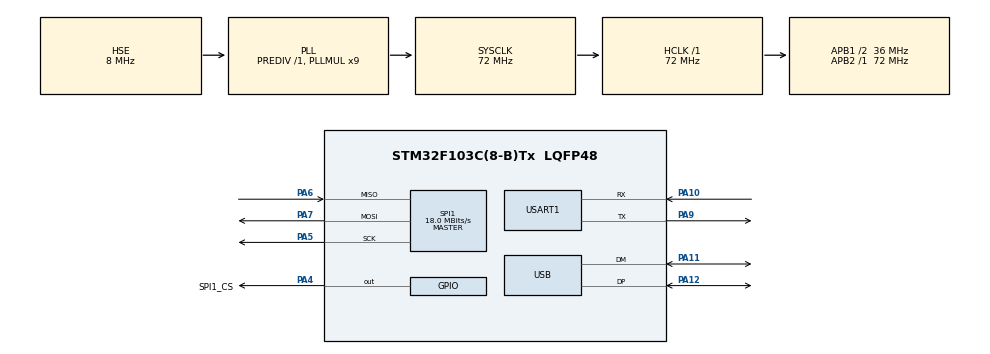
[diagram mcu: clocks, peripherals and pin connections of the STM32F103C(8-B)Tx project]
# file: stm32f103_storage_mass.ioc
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FATFS._CODE_PAGE=1
FATFS._FS_MINIMIZE=0
FATFS._FS_NORTC=0
FATFS._MAX_SS=4096
FATFS._MIN_SS=4096
FATFS._STRF_ENCODE=0
FATFS._USE_FASTSEEK=1
FATFS._USE_FIND=1
FATFS._USE_FORWARD=0
Mcu.Family=STM32F1
Mcu.Name=STM32F103C(8-B)Tx
Mcu.Package=LQFP48
NVIC.PriorityGroup=NVIC_PRIORITYGROUP_2
NVIC.USART1_IRQn=true\:3\:3\:true\:false\:true\:true\:true
NVIC.USB_LP_CAN1_RX0_IRQn=true\:0\:0\:false\:false\:true\:false\:true
PA10.Mode=Asynchronous
PA10.Signal=USART1_RX
PA11.Mode=Device
PA11.Signal=USB_DM
PA12.Mode=Device
PA12.Signal=USB_DP
PA13.Mode=Serial_Wire
PA13.Signal=SYS_JTMS-SWDIO
PA14.Mode=Serial_Wire
PA14.Signal=SYS_JTCK-SWCLK
PA4.GPIO_Label=SPI1_CS
PA4.GPIO_PuPd=GPIO_NOPULL
PA4.GPIO_Speed=GPIO_SPEED_FREQ_HIGH
PA4.PinState=GPIO_PIN_SET
PA4.Signal=GPIO_Output
PA5.Mode=Full_Duplex_Master
PA5.Signal=SPI1_SCK
PA6.Mode=Full_Duplex_Master
PA6.Signal=SPI1_MISO
PA7.Mode=Full_Duplex_Master
PA7.Signal=SPI1_MOSI
PA9.Mode=Asynchronous
PA9.Signal=USART1_TX
PD0-OSC_IN.Mode=HSE-External-Oscillator
PD0-OSC_IN.Signal=RCC_OSC_IN
PD1-OSC_OUT.Mode=HSE-External-Oscillator
PD1-OSC_OUT.Signal=RCC_OSC_OUT
ProjectManager.HeapSize=0x00
ProjectManager.StackSize=0x400
ProjectManager.TargetToolchain=MDK-ARM V5
RCC.ADCPresc=RCC_ADCPCLK2_DIV6
RCC.AHBFreq_Value=72000000
RCC.APB1CLKDivider=RCC_HCLK_DIV2
RCC.APB1Freq_Value=36000000
RCC.APB1TimFreq_Value=72000000
RCC.APB2Freq_Value=72000000
RCC.APB2TimFreq_Value=72000000
RCC.HCLKFreq_Value=72000000
RCC.PLLMUL=RCC_PLL_MUL9
RCC.SYSCLKFreq_VALUE=72000000
RCC.SYSCLKSource=RCC_SYSCLKSOURCE_PLLCLK
RCC.USBFreq_Value=48000000
RCC.USBPrescaler=RCC_USBCLKSOURCE_PLL_DIV1_5
SPI1.BaudRatePrescaler=SPI_BAUDRATEPRESCALER_4
SPI1.CLKPhase=SPI_PHASE_2EDGE
SPI1.CLKPolarity=SPI_POLARITY_HIGH
SPI1.CRCCalculation=SPI_CRCCALCULATION_DISABLE
SPI1.CalculateBaudRate=18.0 MBits/s
SPI1.Direction=SPI_DIRECTION_2LINES
SPI1.FirstBit=SPI_FIRSTBIT_MSB
SPI1.Mode=SPI_MODE_MASTER
SPI1.VirtualType=VM_MASTER
USART1.VirtualMode=VM_ASYNC
USB_DEVICE.CLASS_NAME_FS=MSC
USB_DEVICE.MSC_MEDIA_PACKET=4096
USB_DEVICE.USBD_SELF_POWERED=1
USB_DEVICE.VirtualMode=Msc
USB_DEVICE.VirtualModeFS=Msc_FS
VP_FATFS_VS_Generic.Mode=User_defined
VP_USB_DEVICE_VS_USB_DEVICE_MSC_FS.Mode=MSC_FS
board=custom

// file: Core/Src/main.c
/* USER CODE BEGIN Header */
/**
  ******************************************************************************
  * @file           : main.c
  * @brief          : Main program body
  ******************************************************************************
  * @attention
  *
  * <h2><center>&copy; Copyright (c) 2019 STMicroelectronics.
  * All rights reserved.</center></h2>
  *
  * This software component is licensed by ST under Ultimate Liberty license
  * SLA0044, the "License"; You may not use this file except in compliance with
  * the License. You may obtain a copy of the License at:
  *                             www.st.com/SLA0044
  *
  ******************************************************************************
  */
/* USER CODE END Header */

#include "main.h"
#include "fatfs.h"
#include "spi.h"
#include "usart.h"
#include "usb_device.h"
#include "gpio.h"

/* USER CODE BEGIN Includes */
#include "bsp_w25qxx.h"
#include "w25qxx.h"
#include "usbd_storage_if.h"
#include "stdio.h"
/* USER CODE END Includes */

void SystemClock_Config(void);

int main(void)
{

  /* MCU Configuration--------------------------------------------------------*/

  /* Reset of all peripherals, Initializes the Flash interface and the Systick. */
  HAL_Init();

  /* Configure the system clock */
  SystemClock_Config();

  /* Initialize all configured peripherals */
  MX_GPIO_Init();
  MX_USART1_UART_Init();
  MX_USB_DEVICE_Init();
  MX_SPI1_Init();
  MX_FATFS_Init();
  /* USER CODE BEGIN 2 */

	W25QXX_INIT(0);
	extern uint8_t uart1Value;
	HAL_UART_Receive_IT(&huart1, &uart1Value, 1);
	printf("Flash Type:%s \r\n", w25qxx.name);
	printf("Flash Unique ID:%llX \r\n", w25qxx.unique_id);
	printf("Flash Capicity:%.2f KB\r\n", w25qxx.capicity/1024.0);

//	for(int i=0;i<4096/256;i++){
//		for(int j=0;j<256;j++){
//			buf[i*256+j] = j;
//		}
//	}
//	W25QXX_PROG_SECTOR(0,buf,LEN(buf));
//	for(int i=0;i<4096/256;i++){
//		for(int j=0;j<256;j++){
//			buf[i*256+j] = 255-j;
//		}
//	}
//	W25QXX_PROG_SECTOR(0,buf,LEN(buf));
//	for(int i=0;i<4096/256;i++){
//		for(int j=0;j<256;j++){
//			buf[i*256+j] = j;
//		}
//	}
//	W25QXX_READ_DATA(0,buf,LEN(buf));

//	retUSER = f_mount(&USERFatFS, USERPath, 1);
//	if(retUSER != FR_OK){
//		retUSER = FR_OK;
//	}
//	retUSER = f_mkfs(USERPath, 1, 8192);
//	if(retUSER != FR_OK){
//		retUSER = FR_OK;
//	}
//
//
//  retUSER = f_open(&USERFile, "0:/test.txt", FA_OPEN_ALWAYS | FA_WRITE);
//	retUSER = f_write(&USERFile, "nmsl", 4, 0);
  /* USER CODE END 2 */

  /* Infinite loop */
  while (1)
  {

  }
}

void SystemClock_Config(void)
{
  RCC_OscInitTypeDef RCC_OscInitStruct = {0};
  RCC_ClkInitTypeDef RCC_ClkInitStruct = {0};
  RCC_PeriphCLKInitTypeDef PeriphClkInit = {0};

  /** Initializes the CPU, AHB and APB busses clocks
  */
  RCC_OscInitStruct.OscillatorType = RCC_OSCILLATORTYPE_HSE;
  RCC_OscInitStruct.HSEState = RCC_HSE_ON;
  RCC_OscInitStruct.HSEPredivValue = RCC_HSE_PREDIV_DIV1;
  RCC_OscInitStruct.HSIState = RCC_HSI_ON;
  RCC_OscInitStruct.PLL.PLLState = RCC_PLL_ON;
  RCC_OscInitStruct.PLL.PLLSource = RCC_PLLSOURCE_HSE;
  RCC_OscInitStruct.PLL.PLLMUL = RCC_PLL_MUL9;
  if (HAL_RCC_OscConfig(&RCC_OscInitStruct) != HAL_OK)
  {
    Error_Handler();
  }
  /** Initializes the CPU, AHB and APB busses clocks
  */
  RCC_ClkInitStruct.ClockType = RCC_CLOCKTYPE_HCLK|RCC_CLOCKTYPE_SYSCLK
                              |RCC_CLOCKTYPE_PCLK1|RCC_CLOCKTYPE_PCLK2;
  RCC_ClkInitStruct.SYSCLKSource = RCC_SYSCLKSOURCE_PLLCLK;
  RCC_ClkInitStruct.AHBCLKDivider = RCC_SYSCLK_DIV1;
  RCC_ClkInitStruct.APB1CLKDivider = RCC_HCLK_DIV2;
  RCC_ClkInitStruct.APB2CLKDivider = RCC_HCLK_DIV1;

  if (HAL_RCC_ClockConfig(&RCC_ClkInitStruct, FLASH_LATENCY_2) != HAL_OK)
  {
    Error_Handler();
  }
  PeriphClkInit.PeriphClockSelection = RCC_PERIPHCLK_USB;
  PeriphClkInit.UsbClockSelection = RCC_USBCLKSOURCE_PLL_DIV1_5;
  if (HAL_RCCEx_PeriphCLKConfig(&PeriphClkInit) != HAL_OK)
  {
    Error_Handler();
  }
}

void Error_Handler(void)
{
}

#ifdef  USE_FULL_ASSERT
/**
  * @brief  Reports the name of the source file and the source line number
  *         where the assert_param error has occurred.
  * @param  file: pointer to the source file name
  * @param  line: assert_param error line source number
  * @retval None
  */
void assert_failed(uint8_t *file, uint32_t line)
{
  /* USER CODE BEGIN 6 */
  /* User can add his own implementation to report the file name and line number,
     tex: printf("Wrong parameters value: file %s on line %d\r\n", file, line) */
	// printf("Wrong parameters value: file %s on line %d\r\n", file, line);

  /* USER CODE END 6 */
}
#endif /* USE_FULL_ASSERT */

/************************ (C) COPYRIGHT STMicroelectronics *****END OF FILE****/
